# S32K324_M7 register map
Vendor: NXP Semiconductors; File version: 1.1
CPU: CM7 r0p1, little endian, MPU, FPU, VTOR, 4 interrupt priority bits
Registers are 32-bit, read-write, reset 0x0 unless marked. A register's access mark holds for its fields unless they carry their own. Offsets are from the block's base; [hi:lo] are bit positions; {n}, {i} and the like mark numbered series; 'fields as' and 'values as' point back to an identical list.

## LPSPI_0 — LPSPI
Base 0x40358000
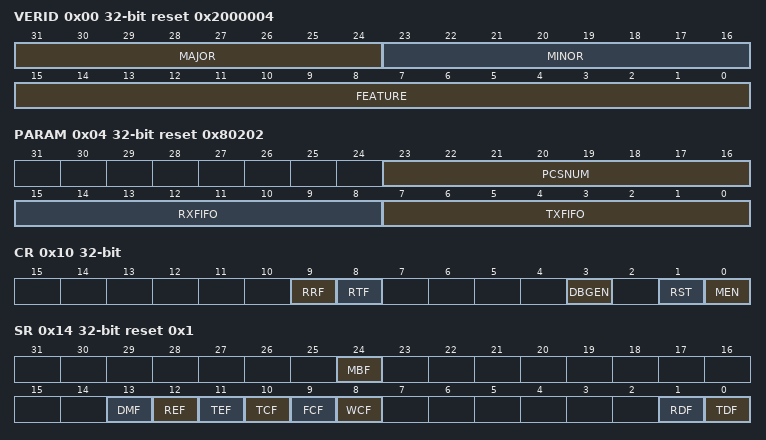
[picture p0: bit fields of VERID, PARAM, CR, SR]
0x00 VERID ro reset 0x2000004 — Version ID
  [31:24] MAJOR — Major Version Number
  [23:16] MINOR — Minor Version Number
  [15:0] FEATURE — Module Identification Number
    4=STANDARD (Standard feature set supporting a 32-bit shift register.)
0x04 PARAM ro reset 0x80202 — Parameter
  [23:16] PCSNUM — PCS Number
  [15:8] RXFIFO — Receive FIFO Size
  [7:0] TXFIFO — Transmit FIFO Size
0x10 CR — Control
  [9] RRF wo — Reset Receive FIFO
    0=NO_EFFECT; 1=RXFIFO_RST (Reset the Receive FIFO. The register bit always reads zero.)
  [8] RTF wo — Reset Transmit FIFO
    0=NO_EFFECT; 1=TXFIFO_RST (Reset the Transmit FIFO. The register bit always reads zero.)
  [3] DBGEN — Debug Enable
    0=DISABLED (LPSPI module is disabled when the CPU is halted. When LPSPI is disabled, the PCS will be negated once the transmit FIFO is empty regardless of the state of TCR register.); 1=ENABLED (LPSPI module is enabled in debug mode)
  [1] RST — Software Reset
    0=NOT_RESET (Module is not reset); 1=RESET (Module is reset)
  [0] MEN — Module Enable
    0=DISABLED (Module is disabled); 1=ENABLED (Module is enabled)
0x14 SR reset 0x1 — Status
  [24] MBF ro — Module Busy Flag
    0=IDLE (LPSPI is idle); 1=BUSY (LPSPI is busy)
  [13] DMF write-1-clears — Data Match Flag
    0=NO_MATCH (Have not received matching data); 1=MATCH (Have received matching data)
  [12] REF write-1-clears — Receive Error Flag
    0=NOT_OVERFLOWED (Receive FIFO has not overflowed); 1=OVERFLOWED (Receive FIFO has overflowed)
  [11] TEF write-1-clears — Transmit Error Flag
    0=NO_UNDERRUN (Transmit FIFO underrun has not occurred); 1=UNDERRUN (Transmit FIFO underrun has occurred)
  [10] TCF write-1-clears — Transfer Complete Flag
    0=NOT_COMPLETED (All transfers have not completed); 1=COMPLETED (All transfers have completed)
  [9] FCF write-1-clears — Frame Complete Flag
    0=NOT_COMPLETED (Frame transfer has not completed); 1=COMPLETED (Frame transfer has completed)
  [8] WCF write-1-clears — Word Complete Flag
    0=NOT_COMPLETED (Transfer of a received word has not yet completed); 1=COMPLETED (Transfer of a received word has completed)
  [1] RDF ro — Receive Data Flag
    0=NOTREADY (Receive Data is not ready); 1=READY (Receive data is ready)
  [0] TDF ro — Transmit Data Flag
    0=TXDATA_NOT_REQST (Transmit data not requested); 1=TXDATA_REQST (Transmit data is requested)
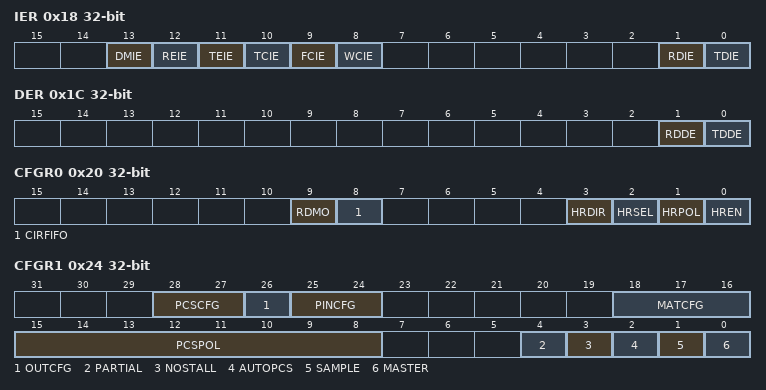
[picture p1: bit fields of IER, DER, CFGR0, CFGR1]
0x18 IER — Interrupt Enable
  [all] fields
    0=DISABLED; 1=ENABLED
  [13] DMIE — Data Match Interrupt Enable
  [12] REIE — Receive Error Interrupt Enable
  [11] TEIE — Transmit Error Interrupt Enable
  [10] TCIE — Transfer Complete Interrupt Enable
  [9] FCIE — Frame Complete Interrupt Enable
  [8] WCIE — Word Complete Interrupt Enable
  [1] RDIE — Receive Data Interrupt Enable
  [0] TDIE — Transmit Data Interrupt Enable
0x1C DER — DMA Enable
  [1] RDDE — Receive Data DMA Enable
    0=DISABLED (DMA request is disabled); 1=ENABLED (DMA request is enabled)
  [0] TDDE — Transmit Data DMA Enable
    values as RDDE
0x20 CFGR0 — Configuration 0
  [9] RDMO — Receive Data Match Only
    0=STORED (Received data is stored in the receive FIFO as in normal operations); 1=DISCARDED (Received data is discarded unless the SR[DMF] = 1)
  [8] CIRFIFO — Circular FIFO Enable
    0=DISABLED (Circular FIFO is disabled); 1=ENABLED (Circular FIFO is enabled)
  [3] HRDIR — Host Request Direction
    0=INPUT (HREQ pin is configured as input); 1=OUTPUT (HREQ pin is configured as output)
  [2] HRSEL — Host Request Select
    0=HREQPIN (Host request input is the HREQ pin); 1=INPUT_TRIGGER (Host request input is the input trigger)
  [1] HRPOL — Host Request Polarity
    0=DISABLED (HREQ pin or input trigger is active high); 1=ENABLED (HREQ pin or input trigger is active low)
  [0] HREN — Host Request Enable
    0=DISABLED (Host request is disabled); 1=ENABLED (Host request is enabled)
0x24 CFGR1 — Configuration 1
  [28:27] PCSCFG — Peripheral Chip Select Configuration
    0=CHIP_SELECT (PCS[7:2] are configured for chip select function); 1=HALFDUPLEX4BIT (PCS[3:2] are configured for half-duplex 4-bit transfers (PCS[3:2] = DATA[3:2])); 3=HALFDUPLEX4AND8BIT (PCS[7:2] are configured for half-duplex 4-bit and 8-bit transfers (PCS[7:2] = DATA[7:2]))
  [26] OUTCFG — Output Configuration
    0=RETAIN_LASTVALUE (Output data retains last value when chip select is negated); 1=TRISTATED (Output data is tristated when chip select is negated)
  [25:24] PINCFG — Pin Configuration
    0=SIN_IN_SOUT_OUT (SIN is used for input data and SOUT is used for output data); 1=SIN_BOTH_IN_OUT (SIN is used for both input and output data, only half-duplex serial transfers are supported); 2=SOUT_BOTH_IN_OUT (SOUT is used for both input and output data, only half-duplex serial transfers are supported); 3=SOUT_IN_SIN_OUT (SOUT is used for input data and SIN is used for output data)
  [18:16] MATCFG — Match Configuration
    0=DISABLED (Match is disabled); 2=ENABLED_FIRSTDATAMATCH (Match is enabled is 1st data word is MATCH0 or MATCH1); 3=ENABLED_ANYDATAMATCH (Match is enabled on any data word equal MATCH0 or MATCH1); 4=ENABLED_DATAMATCH_100 (Match is enabled on data match sequence); 5=ENABLED_DATAMATCH_101 (Match is enabled on data match sequence); 6=ENABLED_DATAMATCH_110 (Match is enabled); 7=ENABLED_DATAMATCH_111 (Match is enabled)
  [15:8] PCSPOL — Peripheral Chip Select Polarity
  [4] PARTIAL — Partial Enable
    0=DISCARDED (Partial words in the receive shift register when PCS negates are discarded.); 1=STORED (Partial words in the receive shift register when PCS negates are stored in the receive FIFO.)
  [3] NOSTALL
    0=DISABLED (Transfers stall when the transmit FIFO is empty or the receive FIFO is full); 1=ENABLED (Transfers do not stall, allowing transmit FIFO underruns or receive FIFO overruns to occur)
  [2] AUTOPCS — Automatic PCS
    0=DISABLED (Automatic PCS generation is disabled); 1=ENABLED (Automatic PCS generation is enabled)
  [1] SAMPLE — Sample Point
    0=ON_SCK_EDGE (Input data is sampled on SCK edge); 1=ON_DELAYED_SCK_EDGE (Input data is sampled on delayed SCK edge)
  [0] MASTER — Master Mode
    0=SLAVE_MODE; 1=MASTER_MODE
0x30 DMR0 — Data Match 0
  [31:0] MATCH0 — Match 0 Value
0x34 DMR1 — Data Match 1
  [31:0] MATCH1 — Match 1 Value
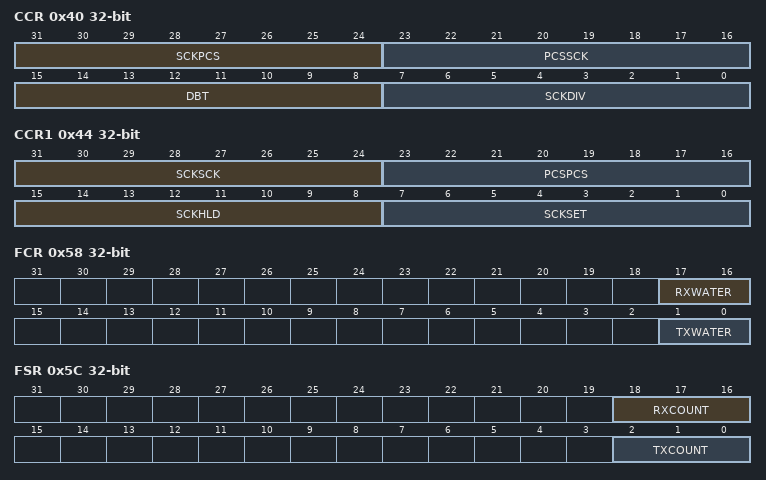
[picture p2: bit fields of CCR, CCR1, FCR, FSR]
0x40 CCR — Clock Configuration
  [31:24] SCKPCS — SCK-to-PCS Delay
  [23:16] PCSSCK — PCS-to-SCK Delay
  [15:8] DBT — Delay Between Transfers
  [7:0] SCKDIV — SCK Divider
0x44 CCR1 — Clock Configuration 1
  [31:24] SCKSCK — SCK Inter-Frame Delay
  [23:16] PCSPCS — PCS to PCS delay
  [15:8] SCKHLD — SCK Hold
  [7:0] SCKSET — SCK Setup
0x58 FCR — FIFO Control
  [17:16] RXWATER — Receive FIFO Watermark
  [1:0] TXWATER — Transmit FIFO Watermark
0x5C FSR ro — FIFO Status
  [18:16] RXCOUNT — Receive FIFO Count
  [2:0] TXCOUNT — Transmit FIFO Count
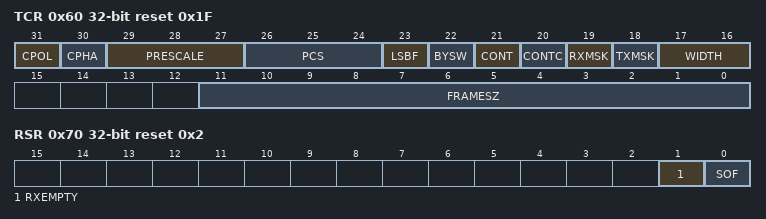
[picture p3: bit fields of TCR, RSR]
0x60 TCR reset 0x1F — Transmit Command
  [31] CPOL — Clock Polarity
    0=INACTIVE_LOW (The inactive state value of SCK is low); 1=INACTIVE_HIGH (The inactive state value of SCK is high)
  [30] CPHA — Clock Phase
    0=CAPTURED; 1=CHANGED
  [29:27] PRESCALE — Prescaler Value
    0=DIVIDEBY1; 1=DIVIDEBY2; 2=DIVIDEBY4; 3=DIVIDEBY8; 4=DIVIDEBY16; 5=DIVIDEBY32; 6=DIVIDEBY64; 7=DIVIDEBY128
  [26:24] PCS — Peripheral Chip Select
    {v}=TX_PCS{v} (Transfer using PCS[{v}]) (v=0..7)
  [23] LSBF — LSB First
    0=MSB_FIRST (Data is transferred MSB first); 1=LSB_FIRST (Data is transferred LSB first)
  [22] BYSW — Byte Swap
    0=DISABLED (Byte swap is disabled); 1=ENABLED (Byte swap is enabled)
  [21] CONT — Continuous Transfer
    0=DISABLED (Continuous transfer is disabled); 1=ENABLED (Continuous transfer is enabled)
  [20] CONTC — Continuing Command
    0=START (Command word for start of new transfer); 1=CONTINUE (Command word for continuing transfer)
  [19] RXMSK — Receive Data Mask
    0=NORMAL (Normal transfer); 1=MASK (Receive data is masked)
  [18] TXMSK — Transmit Data Mask
    0=NORMAL (Normal transfer); 1=MASK (Mask transmit data)
  [17:16] WIDTH — Transfer Width
    0=ONEBIT (1 bit transfer); 1=TWOBIT (2 bit transfer); 2=FOURBIT (4 bit transfer); 3=EIGHTBIT (8 bit transfer)
  [11:0] FRAMESZ — Frame Size
0x64 TDR wo — Transmit Data
  [31:0] DATA
0x70 RSR ro reset 0x2 — Receive Status
  [1] RXEMPTY — RX FIFO Empty
    0=NOT_EMPTY (RX FIFO is not empty); 1=EMPTY (RX FIFO is empty)
  [0] SOF — Start Of Frame
    0=NEXT_DATAWORD (Subsequent data word received after PCS assertion); 1=FIRST_DATAWORD (First data word received after PCS assertion)
0x74 RDR ro — Receive Data
  [31:0] DATA
0x78 RDROR ro — Receive Data Read Only
  [31:0] DATA — Receive Data
0x3FC TCBR wo — Transmit Command Burst
  [31:0] DATA — Command Data
{0x400+4i} TDBR[{i}] (i=0..127) wo — Transmit Data Burst
  [31:0] DATA
{0x600+4i} RDBR[{i}] (i=0..127) ro — Receive Data Burst
  [31:0] DATA

## LPSPI_1 — LPSPI
Base 0x4035C000
Registers as LPSPI_0; these are added or differ:
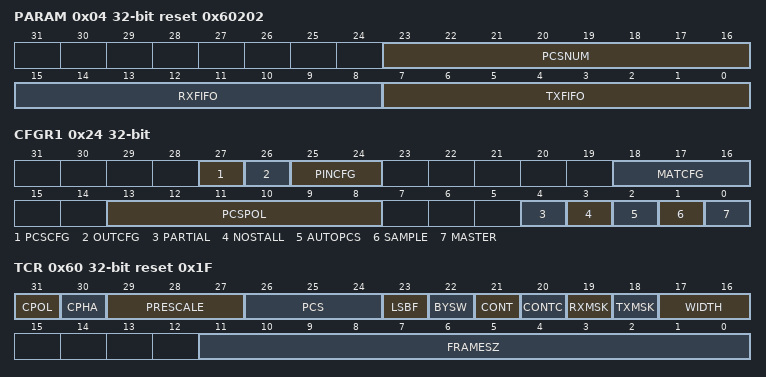
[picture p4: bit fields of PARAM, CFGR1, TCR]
0x04 PARAM ro reset 0x60202 — Parameter
  [23:16] PCSNUM — PCS Number
  [15:8] RXFIFO — Receive FIFO Size
  [7:0] TXFIFO — Transmit FIFO Size
0x24 CFGR1 — Configuration 1
  [27] PCSCFG — Peripheral Chip Select Configuration
    0=CHIP_SELECT (PCS[5:2] are configured for chip select function); 1=HALFDUPLEX4BIT (PCS[3:2] are configured for half-duplex 4-bit transfers (PCS[3:2] = DATA[3:2]))
  [26] OUTCFG — Output Configuration
    0=RETAIN_LASTVALUE (Output data retains last value when chip select is negated); 1=TRISTATED (Output data is tristated when chip select is negated)
  [25:24] PINCFG — Pin Configuration
    values as LPSPI_0.CFGR1.PINCFG
  [18:16] MATCFG — Match Configuration
    values as LPSPI_0.CFGR1.MATCFG
  [13:8] PCSPOL — Peripheral Chip Select Polarity
  [4] PARTIAL — Partial Enable
    0=DISCARDED (Partial words in the receive shift register when PCS negates are discarded.); 1=STORED (Partial words in the receive shift register when PCS negates are stored in the receive FIFO.)
  [3] NOSTALL
    0=DISABLED (Transfers stall when the transmit FIFO is empty or the receive FIFO is full); 1=ENABLED (Transfers do not stall, allowing transmit FIFO underruns or receive FIFO overruns to occur)
  [2] AUTOPCS — Automatic PCS
    0=DISABLED (Automatic PCS generation is disabled); 1=ENABLED (Automatic PCS generation is enabled)
  [1] SAMPLE — Sample Point
    0=ON_SCK_EDGE (Input data is sampled on SCK edge); 1=ON_DELAYED_SCK_EDGE (Input data is sampled on delayed SCK edge)
  [0] MASTER — Master Mode
    0=SLAVE_MODE; 1=MASTER_MODE
0x60 TCR reset 0x1F — Transmit Command
  [31] CPOL — Clock Polarity
    0=INACTIVE_LOW (The inactive state value of SCK is low); 1=INACTIVE_HIGH (The inactive state value of SCK is high)
  [30] CPHA — Clock Phase
    0=CAPTURED; 1=CHANGED
  [29:27] PRESCALE — Prescaler Value
    0=DIVIDEBY1; 1=DIVIDEBY2; 2=DIVIDEBY4; 3=DIVIDEBY8; 4=DIVIDEBY16; 5=DIVIDEBY32; 6=DIVIDEBY64; 7=DIVIDEBY128
  [26:24] PCS — Peripheral Chip Select
    {v}=TX_PCS{v} (Transfer using PCS[{v}]) (v=0..5)
  [23] LSBF — LSB First
    0=MSB_FIRST (Data is transferred MSB first); 1=LSB_FIRST (Data is transferred LSB first)
  [22] BYSW — Byte Swap
    0=DISABLED (Byte swap is disabled); 1=ENABLED (Byte swap is enabled)
  [21] CONT — Continuous Transfer
    0=DISABLED (Continuous transfer is disabled); 1=ENABLED (Continuous transfer is enabled)
  [20] CONTC — Continuing Command
    0=START (Command word for start of new transfer); 1=CONTINUE (Command word for continuing transfer)
  [19] RXMSK — Receive Data Mask
    0=NORMAL (Normal transfer); 1=MASK (Receive data is masked)
  [18] TXMSK — Transmit Data Mask
    0=NORMAL (Normal transfer); 1=MASK (Mask transmit data)
  [17:16] WIDTH — Transfer Width
    0=ONEBIT (1 bit transfer); 1=TWOBIT (2 bit transfer); 2=FOURBIT (4 bit transfer)
  [11:0] FRAMESZ — Frame Size

## LPSPI_2 — LPSPI
Base 0x40360000
Same registers: LPSPI_3 0x40364000, LPSPI_4 0x404BC000, LPSPI_5 0x404C0000
Registers as LPSPI_0; these are added or differ:
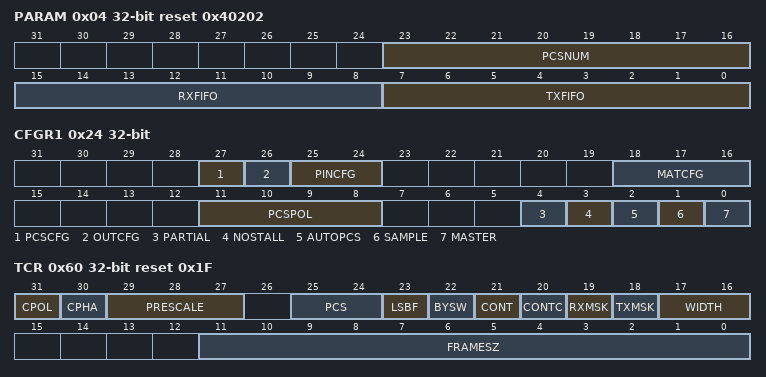
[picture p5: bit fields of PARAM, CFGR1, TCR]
0x04 PARAM ro reset 0x40202 — Parameter
  [23:16] PCSNUM — PCS Number
  [15:8] RXFIFO — Receive FIFO Size
  [7:0] TXFIFO — Transmit FIFO Size
0x24 CFGR1 — Configuration 1
  [27] PCSCFG — Peripheral Chip Select Configuration
    0=CHIP_SELECT (PCS[3:2] are configured for chip select function); 1=HALFDUPLEX4BIT (PCS[3:2] are configured for half-duplex 4-bit transfers (PCS[3:2] = DATA[3:2]))
  [26] OUTCFG — Output Configuration
    0=RETAIN_LASTVALUE (Output data retains last value when chip select is negated); 1=TRISTATED (Output data is tristated when chip select is negated)
  [25:24] PINCFG — Pin Configuration
    values as LPSPI_0.CFGR1.PINCFG
  [18:16] MATCFG — Match Configuration
    values as LPSPI_0.CFGR1.MATCFG
  [11:8] PCSPOL — Peripheral Chip Select Polarity
  [4] PARTIAL — Partial Enable
    0=DISCARDED (Partial words in the receive shift register when PCS negates are discarded.); 1=STORED (Partial words in the receive shift register when PCS negates are stored in the receive FIFO.)
  [3] NOSTALL
    0=DISABLED (Transfers stall when the transmit FIFO is empty or the receive FIFO is full); 1=ENABLED (Transfers do not stall, allowing transmit FIFO underruns or receive FIFO overruns to occur)
  [2] AUTOPCS — Automatic PCS
    0=DISABLED (Automatic PCS generation is disabled); 1=ENABLED (Automatic PCS generation is enabled)
  [1] SAMPLE — Sample Point
    0=ON_SCK_EDGE (Input data is sampled on SCK edge); 1=ON_DELAYED_SCK_EDGE (Input data is sampled on delayed SCK edge)
  [0] MASTER — Master Mode
    0=SLAVE_MODE; 1=MASTER_MODE
0x60 TCR reset 0x1F — Transmit Command
  [31] CPOL — Clock Polarity
    0=INACTIVE_LOW (The inactive state value of SCK is low); 1=INACTIVE_HIGH (The inactive state value of SCK is high)
  [30] CPHA — Clock Phase
    0=CAPTURED; 1=CHANGED
  [29:27] PRESCALE — Prescaler Value
    0=DIVIDEBY1; 1=DIVIDEBY2; 2=DIVIDEBY4; 3=DIVIDEBY8; 4=DIVIDEBY16; 5=DIVIDEBY32; 6=DIVIDEBY64; 7=DIVIDEBY128
  [25:24] PCS — Peripheral Chip Select
    {v}=TX_PCS{v} (Transfer using PCS[{v}]) (v=0..3)
  [23] LSBF — LSB First
    0=MSB_FIRST (Data is transferred MSB first); 1=LSB_FIRST (Data is transferred LSB first)
  [22] BYSW — Byte Swap
    0=DISABLED (Byte swap is disabled); 1=ENABLED (Byte swap is enabled)
  [21] CONT — Continuous Transfer
    0=DISABLED (Continuous transfer is disabled); 1=ENABLED (Continuous transfer is enabled)
  [20] CONTC — Continuing Command
    0=START (Command word for start of new transfer); 1=CONTINUE (Command word for continuing transfer)
  [19] RXMSK — Receive Data Mask
    0=NORMAL (Normal transfer); 1=MASK (Receive data is masked)
  [18] TXMSK — Transmit Data Mask
    0=NORMAL (Normal transfer); 1=MASK (Mask transmit data)
  [17:16] WIDTH — Transfer Width
    0=ONEBIT (1 bit transfer); 1=TWOBIT (2 bit transfer); 2=FOURBIT (4 bit transfer)
  [11:0] FRAMESZ — Frame Size
